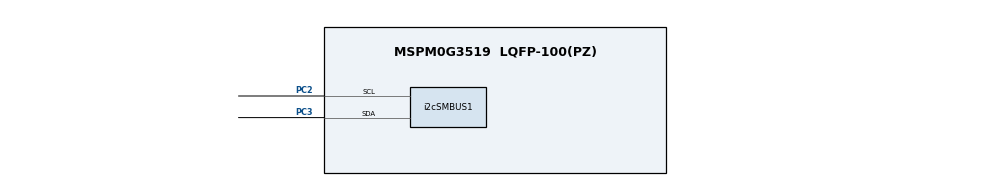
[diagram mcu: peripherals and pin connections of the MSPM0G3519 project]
//@cliArgs --device "MSPM0G351X" --package "LQFP-100(PZ)" --part "Default"
//@v2CliArgs --device "MSPM0G3519" --package "LQFP-100(PZ)"
// @cliArgs --board /ti/boards/LP_MSPM0G3519 --rtos nortos

/**
 * Import the modules used in this configuration.
 */
const SYSCTL        = scripting.addModule("/ti/driverlib/SYSCTL");
const i2cSMBUS      = scripting.addModule("/ti/driverlib/i2cSMBUS", {}, false);
const i2cSMBUS1     = i2cSMBUS.addInstance();
const ProjectConfig = scripting.addModule("/ti/project_config/ProjectConfig");

const Board = scripting.addModule("/ti/driverlib/Board", {}, false);

SYSCTL.peripheral.$assign = "SYSCTL";

i2cSMBUS1.basicEnableController             = true;
i2cSMBUS1.$name                             = "SMB_I2C";
i2cSMBUS1.enableTimeoutA                    = true;
i2cSMBUS1.intGeneric                        = ["TIMEOUT_A"];
i2cSMBUS1.enableControllerPEC               = true;
i2cSMBUS1.intController                     = ["ARBITRATION_LOST","NACK","PEC_RX_ERROR","RXFIFO_TRIGGER","START","STOP","TXFIFO_TRIGGER"];
i2cSMBUS1.timeoutACount                     = 135;
i2cSMBUS1.peripheral.$assign                = "I2C2";
i2cSMBUS1.peripheral.sdaPin.$assign         = "PC3";
i2cSMBUS1.peripheral.sclPin.$assign         = "PC2";

ProjectConfig.genLibSMBUS = true;
